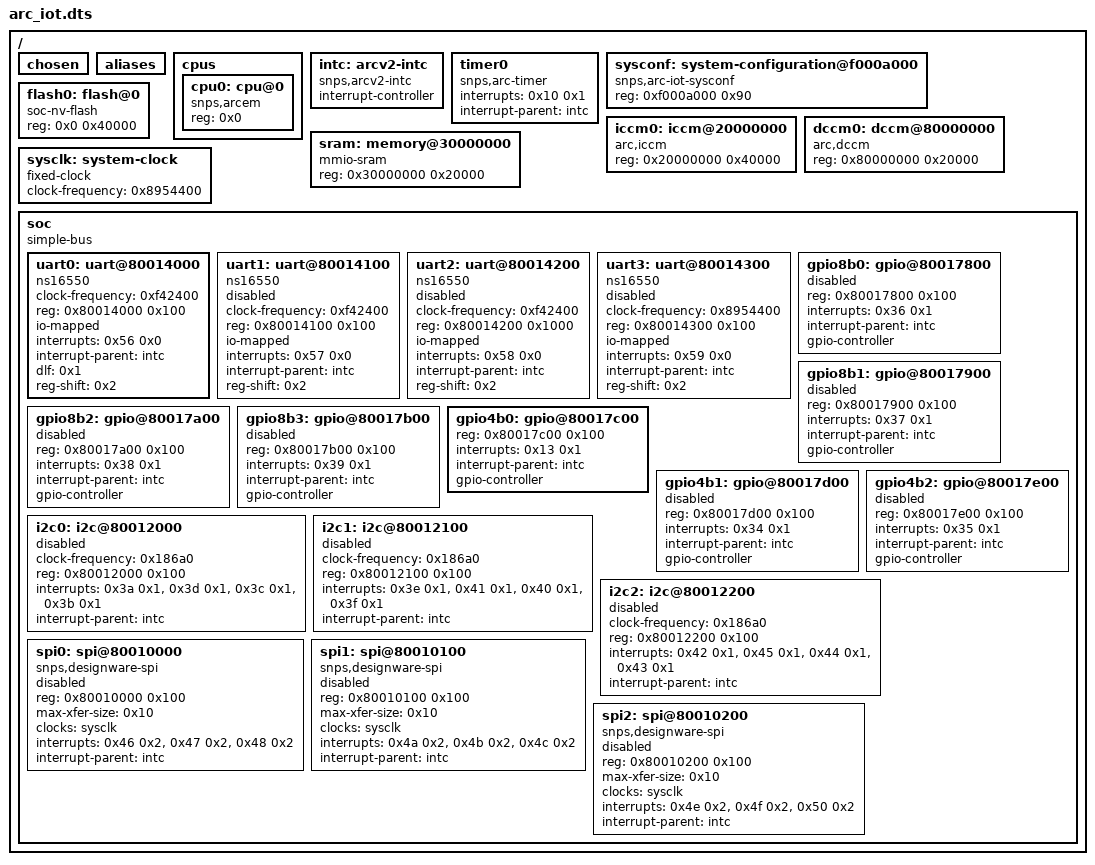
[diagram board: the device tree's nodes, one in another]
/dts-v1/;

/ {
	#address-cells = < 0x1 >;
	#size-cells = < 0x1 >;
	chosen {
	};
	aliases {
	};
	cpus {
		#address-cells = < 0x1 >;
		#size-cells = < 0x0 >;
		cpu0: cpu@0 {
			device_type = "cpu";
			compatible = "snps,arcem";
			reg = < 0x0 >;
		};
	};
	intc: arcv2-intc {
		compatible = "snps,arcv2-intc";
		interrupt-controller;
		#interrupt-cells = < 0x2 >;
		phandle = < 0x1 >;
	};
	timer0: timer0 {
		compatible = "snps,arc-timer";
		interrupts = < 0x10 0x1 >;
		interrupt-parent = < &intc >;
	};
	sysconf: system-configuration@f000a000 {
		compatible = "snps,arc-iot-sysconf";
		reg = < 0xf000a000 0x90 >;
	};
	iccm0: iccm@20000000 {
		compatible = "arc,iccm";
		reg = < 0x20000000 0x40000 >;
	};
	dccm0: dccm@80000000 {
		compatible = "arc,dccm";
		reg = < 0x80000000 0x20000 >;
	};
	sram: memory@30000000 {
		compatible = "mmio-sram";
		reg = < 0x30000000 0x20000 >;
	};
	flash0: flash@0 {
		compatible = "soc-nv-flash";
		reg = < 0x0 0x40000 >;
	};
	sysclk: system-clock {
		compatible = "fixed-clock";
		clock-frequency = < 0x8954400 >;
		#clock-cells = < 0x0 >;
		phandle = < 0x2 >;
	};
	soc {
		#address-cells = < 0x1 >;
		#size-cells = < 0x1 >;
		compatible = "simple-bus";
		ranges;
		uart0: uart@80014000 {
			compatible = "ns16550";
			clock-frequency = < 0xf42400 >;
			reg = < 0x80014000 0x100 >;
			io-mapped;
			interrupts = < 0x56 0x0 >;
			interrupt-parent = < &intc >;
			dlf = < 0x1 >;
			reg-shift = < 0x2 >;
		};
		uart1: uart@80014100 {
			compatible = "ns16550";
			clock-frequency = < 0xf42400 >;
			reg = < 0x80014100 0x100 >;
			io-mapped;
			interrupts = < 0x57 0x0 >;
			interrupt-parent = < &intc >;
			reg-shift = < 0x2 >;
			status = "disabled";
		};
		uart2: uart@80014200 {
			compatible = "ns16550";
			clock-frequency = < 0xf42400 >;
			reg = < 0x80014200 0x1000 >;
			io-mapped;
			interrupts = < 0x58 0x0 >;
			interrupt-parent = < &intc >;
			reg-shift = < 0x2 >;
			status = "disabled";
		};
		uart3: uart@80014300 {
			compatible = "ns16550";
			clock-frequency = < 0x8954400 >;
			reg = < 0x80014300 0x100 >;
			io-mapped;
			interrupts = < 0x59 0x0 >;
			interrupt-parent = < &intc >;
			reg-shift = < 0x2 >;
			status = "disabled";
		};
		gpio8b0: gpio@80017800 {
			reg = < 0x80017800 0x100 >;
			interrupts = < 0x36 0x1 >;
			interrupt-parent = < &intc >;
			gpio-controller;
			#gpio-cells = < 0x2 >;
			status = "disabled";
		};
		gpio8b1: gpio@80017900 {
			reg = < 0x80017900 0x100 >;
			interrupts = < 0x37 0x1 >;
			interrupt-parent = < &intc >;
			gpio-controller;
			#gpio-cells = < 0x2 >;
			status = "disabled";
		};
		gpio8b2: gpio@80017a00 {
			reg = < 0x80017a00 0x100 >;
			interrupts = < 0x38 0x1 >;
			interrupt-parent = < &intc >;
			gpio-controller;
			#gpio-cells = < 0x2 >;
			status = "disabled";
		};
		gpio8b3: gpio@80017b00 {
			reg = < 0x80017b00 0x100 >;
			interrupts = < 0x39 0x1 >;
			interrupt-parent = < &intc >;
			gpio-controller;
			#gpio-cells = < 0x2 >;
			status = "disabled";
		};
		gpio4b0: gpio@80017c00 {
			reg = < 0x80017c00 0x100 >;
			interrupts = < 0x13 0x1 >;
			interrupt-parent = < &intc >;
			gpio-controller;
			#gpio-cells = < 0x2 >;
		};
		gpio4b1: gpio@80017d00 {
			reg = < 0x80017d00 0x100 >;
			interrupts = < 0x34 0x1 >;
			interrupt-parent = < &intc >;
			gpio-controller;
			#gpio-cells = < 0x2 >;
			status = "disabled";
		};
		gpio4b2: gpio@80017e00 {
			reg = < 0x80017e00 0x100 >;
			interrupts = < 0x35 0x1 >;
			interrupt-parent = < &intc >;
			gpio-controller;
			#gpio-cells = < 0x2 >;
			status = "disabled";
		};
		i2c0: i2c@80012000 {
			clock-frequency = < 0x186a0 >;
			#address-cells = < 0x1 >;
			#size-cells = < 0x0 >;
			reg = < 0x80012000 0x100 >;
			interrupts = < 0x3a 0x1 >, < 0x3d 0x1 >, < 0x3c 0x1 >, < 0x3b 0x1 >;
			interrupt-names = "error", "stop", "tx", "rx";
			interrupt-parent = < &intc >;
			status = "disabled";
		};
		i2c1: i2c@80012100 {
			clock-frequency = < 0x186a0 >;
			#address-cells = < 0x1 >;
			#size-cells = < 0x0 >;
			reg = < 0x80012100 0x100 >;
			interrupts = < 0x3e 0x1 >, < 0x41 0x1 >, < 0x40 0x1 >, < 0x3f 0x1 >;
			interrupt-names = "error", "stop", "tx", "rx";
			interrupt-parent = < &intc >;
			status = "disabled";
		};
		i2c2: i2c@80012200 {
			clock-frequency = < 0x186a0 >;
			#address-cells = < 0x1 >;
			#size-cells = < 0x0 >;
			reg = < 0x80012200 0x100 >;
			interrupts = < 0x42 0x1 >, < 0x45 0x1 >, < 0x44 0x1 >, < 0x43 0x1 >;
			interrupt-names = "error", "stop", "tx", "rx";
			interrupt-parent = < &intc >;
			status = "disabled";
		};
		spi0: spi@80010000 {
			compatible = "snps,designware-spi";
			#address-cells = < 0x1 >;
			#size-cells = < 0x0 >;
			reg = < 0x80010000 0x100 >;
			max-xfer-size = < 0x10 >;
			clocks = < &sysclk >;
			interrupts = < 0x46 0x2 >, < 0x47 0x2 >, < 0x48 0x2 >;
			interrupt-names = "err-int", "rx-avail", "tx-req";
			interrupt-parent = < &intc >;
			status = "disabled";
		};
		spi1: spi@80010100 {
			compatible = "snps,designware-spi";
			#address-cells = < 0x1 >;
			#size-cells = < 0x0 >;
			reg = < 0x80010100 0x100 >;
			max-xfer-size = < 0x10 >;
			clocks = < &sysclk >;
			interrupts = < 0x4a 0x2 >, < 0x4b 0x2 >, < 0x4c 0x2 >;
			interrupt-names = "err-int", "rx-avail", "tx-req";
			interrupt-parent = < &intc >;
			status = "disabled";
		};
		spi2: spi@80010200 {
			compatible = "snps,designware-spi";
			#address-cells = < 0x1 >;
			#size-cells = < 0x0 >;
			reg = < 0x80010200 0x100 >;
			max-xfer-size = < 0x10 >;
			clocks = < &sysclk >;
			interrupts = < 0x4e 0x2 >, < 0x4f 0x2 >, < 0x50 0x2 >;
			interrupt-names = "err-int", "rx-avail", "tx-req";
			interrupt-parent = < &intc >;
			status = "disabled";
		};
	};
};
